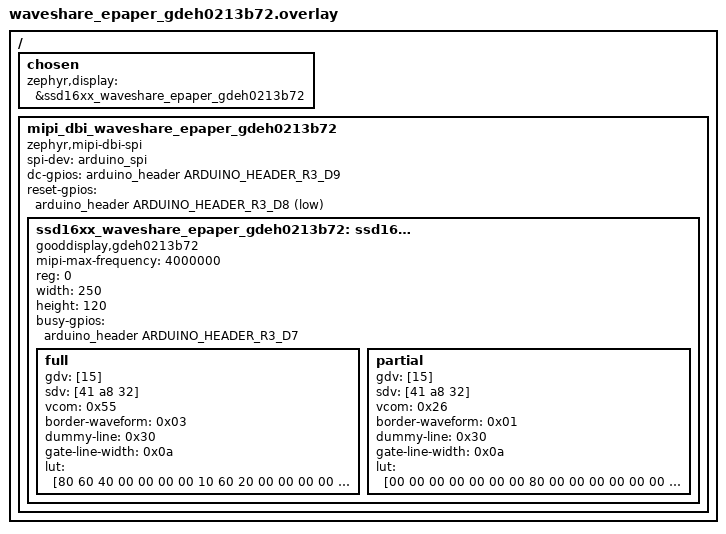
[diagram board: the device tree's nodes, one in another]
/*
 * Copyright (c) 2019, PHYTEC Messtechnik GmbH
 *
 * SPDX-License-Identifier: Apache-2.0
 */

#include "waveshare_epaper_common.dtsi"
#include <zephyr/dt-bindings/gpio/arduino-header-r3.h>

/ {
	chosen {
		zephyr,display = &ssd16xx_waveshare_epaper_gdeh0213b72;
	};

	mipi_dbi_waveshare_epaper_gdeh0213b72 {
		compatible = "zephyr,mipi-dbi-spi";
		spi-dev = <&arduino_spi>;
		dc-gpios = <&arduino_header ARDUINO_HEADER_R3_D9 GPIO_ACTIVE_HIGH>;
		reset-gpios = <&arduino_header ARDUINO_HEADER_R3_D8 GPIO_ACTIVE_LOW>;
		#address-cells = <1>;
		#size-cells = <0>;

		ssd16xx_waveshare_epaper_gdeh0213b72: ssd16xxfb@0 {
			compatible = "gooddisplay,gdeh0213b72", "solomon,ssd1675a";
			mipi-max-frequency = <4000000>;
			reg = <0>;
			width = <250>;
			height = <120>;
			busy-gpios = <&arduino_header ARDUINO_HEADER_R3_D7 GPIO_ACTIVE_HIGH>;

			full {
				gdv = [15];
				sdv = [41 a8 32];
				vcom = <0x55>;
				border-waveform = <0x03>;
				dummy-line = <0x30>;
				gate-line-width = <0x0a>;
				lut = [80 60 40 00 00 00 00
				       10 60 20 00 00 00 00
				       80 60 40 00 00 00 00
				       10 60 20 00 00 00 00
				       00 00 00 00 00 00 00
				       03 03 00 00 02
				       09 09 00 00 02
				       03 03 00 00 02
				       00 00 00 00 00
				       00 00 00 00 00
				       00 00 00 00 00
				       00 00 00 00 00];
			};

			partial {
				gdv = [15];
				sdv = [41 a8 32];
				vcom = <0x26>;
				border-waveform = <0x01>;
				dummy-line = <0x30>;
				gate-line-width = <0x0a>;
				lut = [00 00 00 00 00 00 00
				       80 00 00 00 00 00 00
				       40 00 00 00 00 00 00
				       80 00 00 00 00 00 00
				       00 00 00 00 00 00 00
				       0A 00 00 00 04
				       00 00 00 00 00
				       00 00 00 00 00
				       00 00 00 00 00
				       00 00 00 00 00
				       00 00 00 00 00
				       00 00 00 00 00];
			};
		};
	};
};
